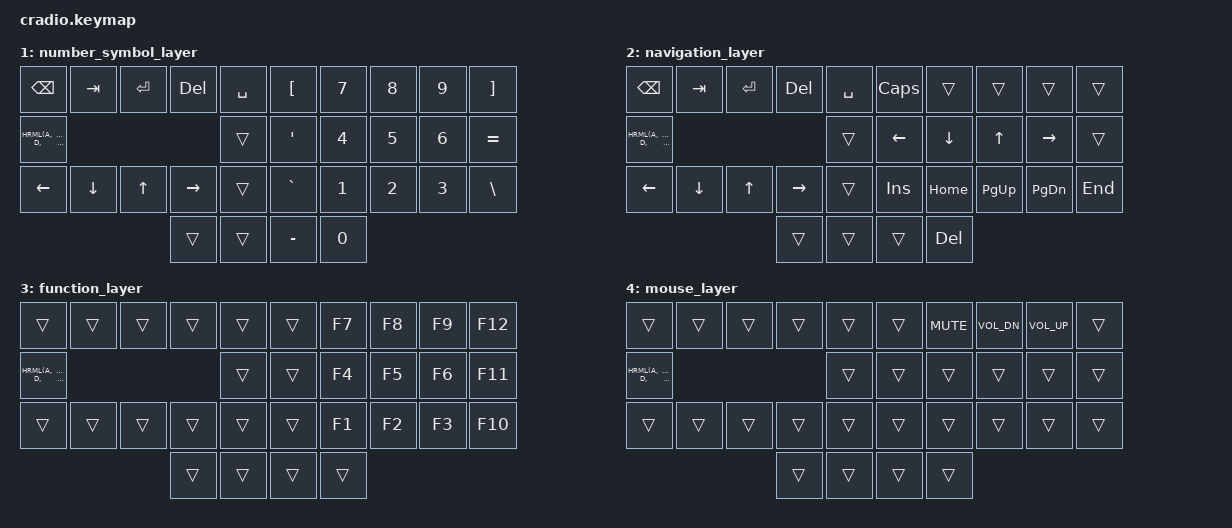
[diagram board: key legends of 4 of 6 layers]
// Copyright (c) 2022 The ZMK Contributors
// SPDX-License-Identifier: MIT

#include <behaviors.dtsi>
#include <dt-bindings/zmk/keys.h>
#include <dt-bindings/zmk/bt.h>

// Home row mods macro
#define HRML(k1,k2,k3,k4) &ht LSHFT k1  &ht LCTRL k2  &ht LALT k3  &ht LGUI k4
#define HRMR(k1,k2,k3,k4) &ht RGUI k1  &ht RALT k2  &ht RCTRL k3  &ht RSHFT k4

/ {
    behaviors {
        ht: hold_tap {
            compatible = "zmk,behavior-hold-tap";
            #binding-cells = <2>;
            flavor = "balanced";
            tapping-term-ms = <180>;
            quick-tap-ms = <0>;
            bindings = <&kp>, <&kp>;
        };
    };

    conditional_layers {
        compatible = "zmk,conditional-layers";
        tri_layer_left {
            if-layers = <1 2>;
            then-layer = <5>;
        };
        tri_layer_right {
            if-layers = <3 4>;
            then-layer = <5>;
        };
    };
    
    combos {
        compatible = "zmk,combos";
        combo_esc_left {
            timeout-ms = <100>;
            key-positions = <1 2 3>;
            bindings = <&kp ESC>;
        };
        combo_esc_right {
            timeout-ms = <100>;
            key-positions = <6 7 8>;
            bindings = <&kp ESC>;
        };
        combo_number_layer_dot {
            timeout-ms = <100>;
            key-positions = <16 17 18>;
            bindings = <&kp KP_DOT>;
            layers=<1>;
        }; 
    };

    keymap { // 0
        compatible = "zmk,keymap";
        default_layer {
            bindings = <
        //╭──────────┬──────────┬──────────┬──────────┬──────────╮   ╭──────────┬──────────┬──────────┬──────────┬──────────╮
        //│  Q       │  W       │  E       │  R       │  T       │   │  Y       │  U       │  I       │  O       │  P       │
            &kp Q      &kp W      &kp E      &kp R      &kp T          &kp Y      &kp U      &kp I      &kp O      &kp P
        //├──────────┼──────────┼──────────┼──────────┼──────────┤   ├──────────┼──────────┼──────────┼──────────┼──────────┤
        //│  A       │  S       │  D       │  F       │  G       │   │  H       │  J       │  K       │  L       │ ; :      │
            HRML(A,     S,         D,         F)     &kp G              &kp H      HRMR(J,    K,         L,        SEMI)
        //├──────────┼──────────┼──────────┼──────────┼──────────┤   ├──────────┼──────────┼──────────┼──────────┼──────────┤
        //│  Z       │  X       │  C       │  V       │  B       │   │  N       │  M       │ , <      │ . >      │ / ?      │
            &kp Z      &kp X      &kp C      &kp V      &kp B          &kp N      &kp M      &kp COMMA  &kp DOT    &kp FSLH
        //╰──────────┴──────────┴──────────┼──────────┼──────────┤   ├──────────┼──────────┼──────────┴──────────┴──────────╯
                                            &lt 1 BSPC  &lt 2 TAB     &lt 3 ENTER &lt 4 SPACE
        //                                 ╰──────────┴──────────╯   ╰──────────┴──────────╯
            >;
        };

        number_symbol_layer { // 1
            bindings = <
        //╭──────────┬──────────┬──────────┬──────────┬──────────╮   ╭──────────┬──────────┬──────────┬──────────┬──────────╮
        //│          │          │          │          │          │   │     {    │     &    │     *    │     (    │     }    │
            &kp BSPC   &kp TAB    &kp ENTER  &kp DEL   &kp SPACE        &kp LBKT   &kp N7     &kp N8     &kp N9     &kp RBKT
        //├──────────┼──────────┼──────────┼──────────┼──────────┤   ├──────────┼──────────┼──────────┼──────────┼──────────┤
        //│          │          │          │          │          │   │     "    │     $    │     %    │     ^    │     +    │
            HRML(A,        S,         D,         F)     &trans         &kp APOS   &kp N4     &kp N5     &kp N6     &kp EQUAL
        //├──────────┼──────────┼──────────┼──────────┼──────────┤   ├──────────┼──────────┼──────────┼──────────┼──────────┤
        //│          │          │          │          │          │   │     ~    │     !    │     @    │     #    │     |    │
            &kp LEFT   &kp DOWN   &kp UP     &kp RIGHT  &trans         &kp GRAVE  &kp N1     &kp N2     &kp N3     &kp BSLH
        //╰──────────┴──────────┴──────────┼──────────┼──────────┤   ├──────────┼──────────┼──────────┴──────────┴──────────╯
        //                                 |          |          |   |    _     |     )    |
                                             &trans     &trans        &kp MINUS   &kp N0
        //                                 ╰──────────┴──────────╯   ╰──────────┴──────────╯
            >;
        };

        navigation_layer { // 2
            bindings = <
        //╭──────────┬──────────┬──────────┬──────────┬──────────╮   ╭──────────┬──────────┬──────────┬──────────┬──────────╮
        //│          │          │          │          │          │   │          │          │          │          │          │
            &kp BSPC   &kp TAB    &kp ENTER  &kp DEL   &kp SPACE       &kp CAPS   &trans     &trans     &trans     &trans
        //├──────────┼──────────┼──────────┼──────────┼──────────┤   ├──────────┼──────────┼──────────┼──────────┼──────────┤
        //│          │          │          │          │          │   │          │          │          │          │          │
            HRML(A,        S,         D,         F)     &trans         &kp LEFT   &kp DOWN   &kp UP     &kp RIGHT  &trans
        //├──────────┼──────────┼──────────┼──────────┼──────────┤   ├──────────┼──────────┼──────────┼──────────┼──────────┤
        //│          │          │          │          │          │   │          │          │          │          │          │
            &kp LEFT   &kp DOWN   &kp UP     &kp RIGHT  &trans         &kp INS    &kp HOME   &kp PG_UP  &kp PG_DN  &kp END
        //╰──────────┴──────────┴──────────┼──────────┼──────────┤   ├──────────┼──────────┼──────────┴──────────┴──────────╯
                                             &trans     &trans         &trans     &kp DEL
        //                                 ╰──────────┴──────────╯   ╰──────────┴──────────╯
            >;
        };
        
        function_layer { // 3
            bindings = <
        //╭──────────┬──────────┬──────────┬──────────┬──────────╮   ╭──────────┬──────────┬──────────┬──────────┬──────────╮
        //│          │          │          │          │          │   │          │          │          │          │          │
            &trans     &trans     &trans     &trans     &trans         &trans     &kp F7     &kp F8     &kp F9     &kp F12
        //├──────────┼──────────┼──────────┼──────────┼──────────┤   ├──────────┼──────────┼──────────┼──────────┼──────────┤
        //│          │          │          │          │          │   │          │          │          │          │          │
            HRML(A,        S,         D,         F)     &trans         &trans     &kp F4     &kp F5     &kp F6     &kp F11
        //├──────────┼──────────┼──────────┼──────────┼──────────┤   ├──────────┼──────────┼──────────┼──────────┼──────────┤
        //│          │          │          │          │          │   │          │          │          │          │          │
            &trans     &trans     &trans     &trans     &trans         &trans     &kp F1     &kp F2     &kp F3     &kp F10
        //╰──────────┴──────────┴──────────┼──────────┼──────────┤   ├──────────┼──────────┼──────────┴──────────┴──────────╯
                                             &trans     &trans         &trans     &trans
        //                                 ╰──────────┴──────────╯   ╰──────────┴──────────╯
            >;
        };
        
        mouse_layer { // 4
            bindings = <
        //╭──────────┬──────────┬──────────┬──────────┬──────────╮   ╭──────────┬──────────┬──────────┬──────────┬──────────╮
        //│          │          │          │          │          │   │          │          │          │          │          │
            &trans     &trans     &trans     &trans     &trans         &trans &kp C_MUTE  &kp C_VOL_DN &kp C_VOL_UP &trans
        //├──────────┼──────────┼──────────┼──────────┼──────────┤   ├──────────┼──────────┼──────────┼──────────┼──────────┤
        //│          │          │          │          │          │   │          │          │          │          │          │
            HRML(A,        S,         D,         F)     &trans         &trans     &trans     &trans     &trans     &trans
        //├──────────┼──────────┼──────────┼──────────┼──────────┤   ├──────────┼──────────┼──────────┼──────────┼──────────┤
        //│          │          │          │          │          │   │          │          │          │          │          │
            &trans     &trans     &trans     &trans     &trans         &trans     &trans     &trans     &trans     &trans
        //╰──────────┴──────────┴──────────┼──────────┼──────────┤   ├──────────┼──────────┼──────────┴──────────┴──────────╯
                                             &trans     &trans         &trans     &trans
        //                                 ╰──────────┴──────────╯   ╰──────────┴──────────╯
            >;
        };
        
        control_layer { // 5
            bindings = <
        //╭──────────┬──────────┬──────────┬──────────┬──────────╮   ╭──────────┬──────────┬──────────┬──────────┬──────────╮
        //│          │          │          │          │          │   |          │          │          │          │          │
         &sys_reset &bt BT_SEL 6 &bt BT_SEL 7 &bt BT_SEL 8 &trans    &sys_reset &bt BT_SEL 6 &bt BT_SEL 7 &bt BT_SEL 8 &trans
        //├──────────┼──────────┼──────────┼──────────┼──────────┤   ├──────────┼──────────┼──────────┼──────────┼──────────┤
        //│          │          │          │          │          │   │          │          │          │          │          │
        &bootloader &bt BT_SEL 3 &bt BT_SEL 4 &bt BT_SEL 5 &trans    &bootloader &bt BT_SEL 3 &bt BT_SEL 4 &bt BT_SEL 5 &trans
        //├──────────┼──────────┼──────────┼──────────┼──────────┤   ├──────────┼──────────┼──────────┼──────────┼──────────┤
        //│          │          │          │          │          │   │          │          │          │          │          │
        &bt BT_CLR  &bt BT_SEL 0 &bt BT_SEL 1 &bt BT_SEL 2 &trans    &bt BT_CLR  &bt BT_SEL 0 &bt BT_SEL 1 &bt BT_SEL 2 &trans
        //╰──────────┴──────────┴──────────┼──────────┼──────────┤   ├──────────┼──────────┼──────────┴──────────┴──────────╯
                                             &trans     &trans         &trans     &trans
        //                                 ╰──────────┴──────────╯   ╰──────────┴──────────╯
            >;
        };
    };
};
